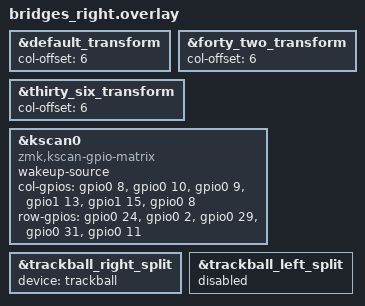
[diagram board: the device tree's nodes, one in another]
/*
 * Copyright (c) 2025 Vincent Franco
 * SPDX-License-Identifier: MIT
 */

#include "bridges.dtsi"
#include "bridges_3610.dtsi"

&default_transform {
  col-offset = <6>;
};

&forty_two_transform {
  col-offset = <6>;
};

&thirty_six_transform {
  col-offset = <6>;
};

&kscan0 {
  compatible = "zmk,kscan-gpio-matrix";
  wakeup-source;

  col-gpios
		= <&gpio0 8 (GPIO_ACTIVE_HIGH | GPIO_PULL_DOWN)>
		, <&gpio0 10  (GPIO_ACTIVE_HIGH | GPIO_PULL_DOWN)>
		, <&gpio0 9 (GPIO_ACTIVE_HIGH | GPIO_PULL_DOWN)>
		, <&gpio1 13 (GPIO_ACTIVE_HIGH | GPIO_PULL_DOWN)>
		, <&gpio1 15 (GPIO_ACTIVE_HIGH | GPIO_PULL_DOWN)>
		, <&gpio0 8 (GPIO_ACTIVE_HIGH | GPIO_PULL_DOWN)>
		
		;

  row-gpios
    = <&gpio0 24 GPIO_ACTIVE_HIGH>
			, <&gpio0 2 GPIO_ACTIVE_HIGH>
            , <&gpio0 29 GPIO_ACTIVE_HIGH>
            , <&gpio0 31 GPIO_ACTIVE_HIGH>
	        , <&gpio0 11 GPIO_ACTIVE_HIGH>;
};

// Overrides for the input-split child node
&trackball_right_split {
  device = <&trackball>;
};

&trackball_left_split {
  status = "disabled";
};
